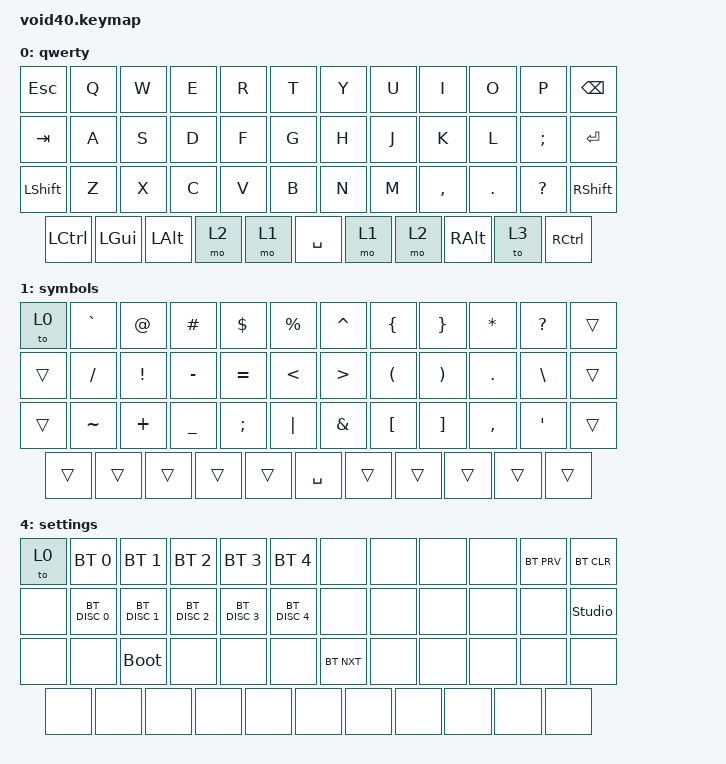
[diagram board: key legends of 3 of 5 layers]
#include <behaviors.dtsi>
#include <dt-bindings/zmk/keys.h>
#include <dt-bindings/zmk/bt.h>

/ {
	combos {
		compatible = "zmk,combos";

		zmk_studio_combo {
			timeout-ms = <50>;
			key-positions = <0 1>;
			bindings = <&studio_unlock>;
		};

		bt_layer_combo {
			timeout-ms = <50>;
			key-positions = <36 46>;
			bindings = <&sl 4>;
		};
	};

	keymap {
		compatible = "zmk,keymap";
		
		/* test { */
		/* 	bindings = <&bt BT_SEL 0 &kp B &kp L &trans &trans &trans &trans &trans &trans &trans &trans &trans */
		/* 	&trans &trans &trans &trans &trans &trans &trans &trans &trans &trans &trans &trans  */
		/* 	&trans &trans &trans &trans &trans &trans &trans &trans &trans &trans &trans &trans */
		/* 	&trans &trans &trans &trans &trans &trans &trans &trans &trans &trans &kp Q>; */
		/* }; */

		qwerty {
			bindings = <
				&kp ESC &kp Q &kp W &kp E &kp R &kp T &kp Y &kp U &kp I &kp O &kp P &kp BSPC
				&kp TAB &kp A &kp S &kp D &kp F &kp G &kp H &kp J &kp K &kp L  &kp SEMI &kp ENTER
				&kp LSHIFT &kp Z &kp X &kp C &kp V &kp B &kp N &kp M &kp COMMA &kp DOT &kp QMARK &kp RSHIFT
				&kp LCTRL &kp LGUI &kp LALT &mo 2 &mo 1 &kp SPACE &mo 1 &mo 2 &kp RALT &to 3 &kp RCTRL
			>;
		};
		symbols {
			bindings = <
				&to 0 &kp GRAVE &kp AT &kp HASH &kp DOLLAR &kp PRCNT &kp CARET &kp LBRC &kp RBRC &kp STAR &kp QMARK &trans
				&trans &kp SLASH &kp EXCL &kp MINUS &kp EQUAL &kp LT &kp GT &kp LPAR &kp RPAR &kp DOT  &kp BSLH &trans
				&trans &kp TILDE &kp PLUS &kp UNDER &kp SEMI &kp PIPE &kp AMPS &kp LBKT &kp RBKT &kp COMMA &kp SQT &trans
				&trans &trans &trans &trans &trans &kp SPACE &trans &trans &trans &trans &trans
			>;
		};
		functions {
			bindings = <
				&to 0 &trans &kp UP &trans &trans &trans &kp C_BRI_DN &kp C_BRI_UP &kp K_VOL_DN &kp K_VOL_UP &kp K_MUTE &trans
				&trans &kp LEFT &kp DOWN &kp RIGHT &trans &trans &kp LEFT &kp DOWN &kp UP &kp RIGHT &trans &trans
				&trans &trans &trans &trans &trans &trans &trans &trans &trans &trans &trans &trans
				&trans &trans &trans &trans &trans &kp SPACE &trans &trans &trans &trans &sl 4 &trans
			>;
		};
		numbers {
			bindings = <
				&to 0 &kp N1 &kp N2 &kp N3 &kp N4 &kp N5 &kp N6 &kp N7 &kp N8 &kp N9 &kp N0 &trans
				&trans &kp F1 &kp F2 &kp F3 &kp F4 &kp F5 &kp F6 &kp F7 &kp F8 &kp F9 &kp F10 &trans
				&trans &kp F11 &kp F12 &trans &trans &trans &trans &trans &trans &trans &trans &trans
				&trans &trans &trans &trans &trans &kp SPACE &trans &trans &trans &trans &trans &trans
			>;
		};
		settings {
			bindings = <
				&to 0 &bt BT_SEL 0 &bt BT_SEL 1 &bt BT_SEL 2 &bt BT_SEL 3 &bt BT_SEL 4 &none &none &none &none &bt BT_PRV &bt BT_CLR
				&none &bt BT_DISC 0 &bt BT_DISC 1 &bt BT_DISC 2 &bt BT_DISC 3 &bt BT_DISC 4 &none &none &none &none &none &studio_unlock
				&none &none &bootloader &none &none &none &bt BT_NXT &none &none &none &none &none
				&none &none &none &none &none &none &none &none &none &none &none
			>;
		};
		locked {
			status = "reserved";
		};
	};
};
